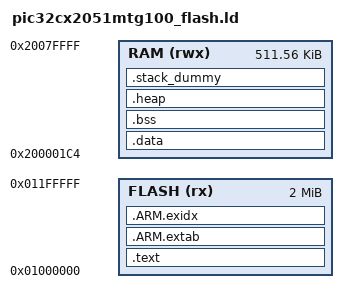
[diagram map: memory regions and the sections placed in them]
/* Linker script for Microchip PIC32CX devices                         */
/*                                                                     */
/* This file is subject to the license terms as defined in ARM's       */
/* CMSIS END USER LICENSE AGREEMENT.pdf, governing the use of          */
/* Example Code.                                                       */
/*                                                                     */
/* Copyright (c) 2021, Microchip Technology Inc.           */
/*                                                                     */
/*                                                                     */

#if !defined(MBED_CONF_TARGET_BOOT_STACK_SIZE)
    #define MBED_CONF_TARGET_BOOT_STACK_SIZE 0x400
#endif

STACK_SIZE = MBED_CONF_TARGET_BOOT_STACK_SIZE;

MEMORY
{
  FLASH (rx) : ORIGIN = 0x01000000, LENGTH = 0x200000
  RAM (rwx)  : ORIGIN = 0x200001C4, LENGTH = 0x7FE3C
}

/* MBED: mbed needs to be able to dynamically set the interrupt vector table.
 * We make room for the table at the very beginning of RAM, i.e. at
 * 0x20000000. We need (16+97 * sizeof(uint32_t) = 452 bytes for PIC32CX */
__vector_size = 0x1c4;

/* Section Definitions */
SECTIONS
{
  .text :
  {
    KEEP(*(.vectors))
    __Vectors_End = .;
    __Vectors_Size = __Vectors_End - __Vectors;
    __end__ = .;

    *(.text*)

    KEEP(*(.init))
    KEEP(*(.fini))

    /* .ctors */
    *crtbegin.o(.ctors)
    *crtbegin?.o(.ctors)
    *(EXCLUDE_FILE(*crtend?.o *crtend.o) .ctors)
    *(SORT(.ctors.*))
    *(.ctors)

    /* .dtors */
    *crtbegin.o(.dtors)
    *crtbegin?.o(.dtors)
    *(EXCLUDE_FILE(*crtend?.o *crtend.o) .dtors)
    *(SORT(.dtors.*))
    *(.dtors)

    *(.rodata*)

    KEEP(*(.eh_frame*))
  } > FLASH

  .ARM.extab :
  {
    *(.ARM.extab* .gnu.linkonce.armextab.*)
  } > FLASH

  __exidx_start = .;
  .ARM.exidx :
  {
    *(.ARM.exidx* .gnu.linkonce.armexidx.*)
  } > FLASH
  __exidx_end = .;

  __etext = .;

  .data : AT (__etext)
  {
    __data_start__ = .;
    PROVIDE( __start_vector_table__ = .);
    . += __vector_size;
    PROVIDE( __end_vector_table__ = .);

    *(.data*)
	
    . = ALIGN (8);
    *(.ram)

    . = ALIGN(8);
    /* preinit data */
    PROVIDE_HIDDEN (__preinit_array_start = .);
    KEEP(*(.preinit_array))
    PROVIDE_HIDDEN (__preinit_array_end = .);

    . = ALIGN(8);
    /* init data */
    PROVIDE_HIDDEN (__init_array_start = .);
    KEEP(*(SORT(.init_array.*)))
    KEEP(*(.init_array))
    PROVIDE_HIDDEN (__init_array_end = .);

    . = ALIGN(8);
    /* finit data */
    PROVIDE_HIDDEN (__fini_array_start = .);
    KEEP(*(SORT(.fini_array.*)))
    KEEP(*(.fini_array))
    PROVIDE_HIDDEN (__fini_array_end = .);

    KEEP(*(.jcr*))
    . = ALIGN(8);
    /* All data end */
    __data_end__ = .;

  } > RAM

  .bss :
  {
    . = ALIGN(8);
    __bss_start__ = .;
    *(.bss*)
    *(COMMON)
    . = ALIGN(8);
    __bss_end__ = .;
  } > RAM

  .heap (COPY):
  {
    __HeapBase = .;
    __end__ = .;
    end = __end__;
    _end = __end__;
    KEEP(*(.heap*))
    . = ORIGIN(RAM) + LENGTH(RAM) - STACK_SIZE;
    __HeapLimit = .;
  } > RAM

  /* .stack_dummy section doesn't contains any symbols. It is only
   * used for linker to calculate size of stack sections, and assign
   * values to stack symbols later */
  .stack_dummy (COPY):
  {
    KEEP(*(.stack*))
  } > RAM

  /* Set stack top to end of RAM, and stack limit move down by
   * size of stack_dummy section */
  __StackTop = ORIGIN(RAM) + LENGTH(RAM);
  __StackLimit = __StackTop - STACK_SIZE;
  PROVIDE(__stack = __StackTop);

  /* Check if data + heap + stack exceeds RAM limit */
  ASSERT(__StackLimit >= __HeapLimit, "region RAM overflowed with stack")

  /* Check if FLASH usage exceeds FLASH size */
  ASSERT(ORIGIN(FLASH) + LENGTH(FLASH) >= (__etext + SIZEOF(.data)), "FLASH memory overflowed !")
}
